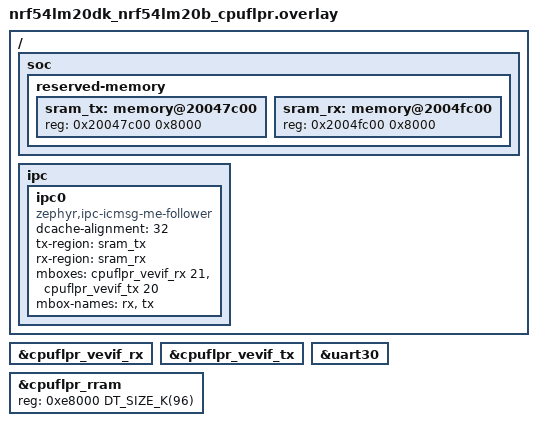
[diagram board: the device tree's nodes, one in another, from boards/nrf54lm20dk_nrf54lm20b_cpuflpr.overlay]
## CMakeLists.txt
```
#
# Copyright (c) 2022 Nordic Semiconductor ASA
#
# SPDX-License-Identifier: Apache-2.0
#

cmake_minimum_required(VERSION 3.20.0)

find_package(Zephyr REQUIRED HINTS $ENV{ZEPHYR_BASE})
project(ipc_service_remote)

target_sources(app PRIVATE src/main.c src/flpr_log_backend.c)
zephyr_include_directories(${CMAKE_CURRENT_SOURCE_DIR}/../include)
```

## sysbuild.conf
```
# FLPR is a sysbuild child image; do not add the VPR bootstrap launcher sample.
SB_CONFIG_VPR_LAUNCHER=n
```

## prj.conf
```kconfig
CONFIG_PRINTK=y
CONFIG_LOG_PRINTK=n

CONFIG_IPC_SERVICE=y
CONFIG_MBOX=y

CONFIG_LOG=y
CONFIG_LOG_DEFAULT_LEVEL=2
CONFIG_LOG_MODE_DEFERRED=y
CONFIG_IPC_SERVICE_LOG_LEVEL_INF=y

CONFIG_HEAP_MEM_POOL_SIZE=2048
```

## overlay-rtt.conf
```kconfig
# Optional: free uart30 - FLPR printk/boot on RTT.
# Operational logs still go over IPC to cpuapp CDC1 (flpr_log_backend).

CONFIG_USE_SEGGER_RTT=y
CONFIG_RTT_CONSOLE=y
CONFIG_UART_CONSOLE=n

# Do not block FLPR boot if no RTT Viewer is attached.
CONFIG_SEGGER_RTT_MODE_NO_BLOCK_SKIP=y
CONFIG_RTT_TX_RETRY_CNT=0

# Keep printk on RTT_CONSOLE; do not enable blocking LOG RTT backend.
CONFIG_LOG_BACKEND_RTT=n
CONFIG_LOG_PRINTK=n
```

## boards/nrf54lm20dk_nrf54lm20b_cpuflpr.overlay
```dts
/ {
	soc {
		reserved-memory {
			#address-cells = <1>;
			#size-cells = <1>;

			sram_tx: memory@20047c00 {
				reg = <0x20047c00 0x8000>;
			};

			sram_rx: memory@2004fc00 {
				reg = <0x2004fc00 0x8000>;
			};
		};
	};

	ipc {
		ipc0: ipc0 {
			compatible = "zephyr,ipc-icmsg-me-follower";
			dcache-alignment = <32>;
			tx-region = <&sram_tx>;
			rx-region = <&sram_rx>;
			mboxes = <&cpuflpr_vevif_rx 21>, <&cpuflpr_vevif_tx 20>;
			mbox-names = "rx", "tx";
			status = "okay";
		};
	};
};

&cpuflpr_vevif_rx {
	status = "okay";
};

&cpuflpr_vevif_tx {
	status = "okay";
};

&uart30 {
	/delete-property/ hw-flow-control;
};

/*
 * Coupled OTA: link FLPR payload at in-slot storage (matches cpuapp
 * cpuflpr_code_partition @ 0xE8000). Node name stays rram@1e5000 (SoC dtsi).
 */
&cpuflpr_rram {
	reg = <0xe8000 DT_SIZE_K(96)>;
	ranges = <0x0 0xe8000 DT_SIZE_K(96)>;
};
```

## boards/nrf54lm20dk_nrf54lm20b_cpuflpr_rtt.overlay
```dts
/*
 * Optional FLPR RTT console - apply with remote/overlay-rtt.conf.
 * Disables debugger uart30; local printk goes to RTT.
 */

/ {
	chosen {
		/delete-property/ zephyr,console;
		/delete-property/ zephyr,shell-uart;
	};
};

&uart30 {
	status = "disabled";
};
```

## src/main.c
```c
#include "flpr_ipc_proto.h"

#include <string.h>

#include <zephyr/device.h>
#include <zephyr/ipc/ipc_service.h>
#include <zephyr/kernel.h>
#include <zephyr/sys/printk.h>

#define STACKSIZE 2048
#define PRIORITY  K_PRIO_PREEMPT(2)

static const struct device *ipc0_dev;
static struct ipc_ept ept_log;
static struct ipc_ept ept_ctrl;

static K_SEM_DEFINE(log_bound_sem, 0, 1);
static K_SEM_DEFINE(ctrl_bound_sem, 0, 1);

static volatile bool log_bound;
static volatile bool ctrl_bound;
static uint32_t heartbeat;

int flpr_remote_send_log(const char *text, size_t len)
{
	if (!log_bound || text == NULL || len == 0) {
		return -ENOTCONN;
	}

	if (len > FLPR_LOG_MAX_LEN) {
		len = FLPR_LOG_MAX_LEN;
	}

	return ipc_service_send(&ept_log, text, len);
}

static void ept_log_bound(void *priv)
{
	ARG_UNUSED(priv);
	log_bound = true;
	k_sem_give(&log_bound_sem);
	/* #region agent log */
	printk("IPC[F] BOUND flpr_log @ %u ms\n", k_uptime_get_32());
	/* #endregion */
	printk("REMOTE: flpr_log bound\n");
}

static void ept_ctrl_bound(void *priv)
{
	ARG_UNUSED(priv);
	ctrl_bound = true;
	k_sem_give(&ctrl_bound_sem);
	/* #region agent log */
	printk("IPC[F] BOUND flpr_ctrl @ %u ms\n", k_uptime_get_32());
	/* #endregion */
	printk("REMOTE: flpr_ctrl bound\n");
}

static int send_ctrl(uint8_t opcode, uint8_t seq, const void *payload, uint16_t payload_len)
{
	uint8_t buf[sizeof(struct flpr_ctrl_hdr) + sizeof(struct flpr_stats) + FLPR_LOG_MAX_LEN];
	struct flpr_ctrl_hdr *hdr = (struct flpr_ctrl_hdr *)buf;

	if (!ctrl_bound) {
		return -ENOTCONN;
	}
	if (payload_len > (sizeof(buf) - sizeof(*hdr))) {
		return -EINVAL;
	}

	hdr->opcode = opcode;
	hdr->seq = seq;
	hdr->len = payload_len;
	if (payload_len && payload != NULL) {
		memcpy(buf + sizeof(*hdr), payload, payload_len);
	}

	return ipc_service_send(&ept_ctrl, buf, sizeof(*hdr) + payload_len);
}

static int send_log_line(const char *text)
{
	return flpr_remote_send_log(text, text ? strlen(text) : 0);
}

static void send_stats(void)
{
	struct flpr_stats stats = {
		.uptime_ms = k_uptime_get_32(),
		.heartbeat = ++heartbeat,
		.free_stack = 0,
	};

	(void)send_ctrl(FLPR_CTRL_OPCODE_STATS, 0, &stats, sizeof(stats));
}

static void ept_log_recv(const void *data, size_t len, void *priv)
{
	ARG_UNUSED(data);
	ARG_UNUSED(len);
	ARG_UNUSED(priv);
}

static void ept_ctrl_recv(const void *data, size_t len, void *priv)
{
	ARG_UNUSED(priv);

	if (data == NULL || len < sizeof(struct flpr_ctrl_hdr)) {
		return;
	}

	const struct flpr_ctrl_hdr *hdr = data;
	const uint8_t *payload = (const uint8_t *)data + sizeof(*hdr);

	switch (hdr->opcode) {
	case FLPR_CTRL_OPCODE_PING:
		(void)send_ctrl(FLPR_CTRL_OPCODE_PONG, hdr->seq, NULL, 0);
		break;
	case FLPR_CTRL_OPCODE_STATS_REQ:
		send_stats();
		break;
	case FLPR_CTRL_OPCODE_LOG_REQ: {
		char line[FLPR_LOG_MAX_LEN + 1];
		uint16_t n = hdr->len;

		if (n > FLPR_LOG_MAX_LEN) {
			n = FLPR_LOG_MAX_LEN;
		}
		if (n > 0) {
			memcpy(line, payload, n);
		}
		line[n] = '\0';
		printk("REMOTE log-req: %s\n", line);
		(void)send_log_line(line);
		break;
	}
	default:
		break;
	}
}

static struct ipc_ept_cfg ept_log_cfg = {
	.name = FLPR_IPC_EPT_LOG_NAME,
	.cb = {
		.bound = ept_log_bound,
		.received = ept_log_recv,
	},
};

static struct ipc_ept_cfg ept_ctrl_cfg = {
	.name = FLPR_IPC_EPT_CTRL_NAME,
	.cb = {
		.bound = ept_ctrl_bound,
		.received = ept_ctrl_recv,
	},
};

static void heartbeat_entry(void *a, void *b, void *c)
{
	ARG_UNUSED(a);
	ARG_UNUSED(b);
	ARG_UNUSED(c);

	while (1) {
		if (ctrl_bound) {
			send_stats();
		}
		if (log_bound) {
			char msg[48];

			snprintk(msg, sizeof(msg), "FLPR heartbeat %u", heartbeat);
			(void)send_log_line(msg);
			printk("%s\n", msg);
		}
		k_sleep(K_SECONDS(5));
	}
}

K_THREAD_DEFINE(hb_tid, STACKSIZE, heartbeat_entry, NULL, NULL, NULL, PRIORITY, 0, 0);

int main(void)
{
	int ret;
	uint32_t t0;

	/* #region agent log */
	printk("IPC[F] main start @ %u ms\n", k_uptime_get_32());
	/* #endregion */
	printk("FLPR remote IPC stub starting\n");

	ipc0_dev = DEVICE_DT_GET(DT_NODELABEL(ipc0));
	if (!device_is_ready(ipc0_dev)) {
		printk("ipc0 not ready\n");
		return 0;
	}

	/* #region agent log */
	printk("IPC[F] open_instance enter @ %u ms\n", k_uptime_get_32());
	/* #endregion */
	ret = ipc_service_open_instance(ipc0_dev);
	/* #region agent log */
	printk("IPC[F] open_instance ret=%d @ %u ms\n", ret, k_uptime_get_32());
	/* #endregion */
	if (ret < 0 && ret != -EALREADY) {
		printk("open_instance failed (%d)\n", ret);
		return 0;
	}

	t0 = k_uptime_get_32();
	/* #region agent log */
	printk("IPC[F] register flpr_log enter @ %u ms\n", t0);
	/* #endregion */
	ret = ipc_service_register_endpoint(ipc0_dev, &ept_log, &ept_log_cfg);
	/* #region agent log */
	printk("IPC[F] register flpr_log ret=%d dt=%u ms\n", ret, k_uptime_get_32() - t0);
	/* #endregion */
	if (ret < 0) {
		printk("register flpr_log failed (%d)\n", ret);
		return 0;
	}

	t0 = k_uptime_get_32();
	/* #region agent log */
	printk("IPC[F] register flpr_ctrl enter @ %u ms\n", t0);
	/* #endregion */
	ret = ipc_service_register_endpoint(ipc0_dev, &ept_ctrl, &ept_ctrl_cfg);
	/* #region agent log */
	printk("IPC[F] register flpr_ctrl ret=%d dt=%u ms\n", ret, k_uptime_get_32() - t0);
	/* #endregion */
	if (ret < 0) {
		printk("register flpr_ctrl failed (%d)\n", ret);
		return 0;
	}

	/* #region agent log */
	printk("IPC[F] sem log wait enter @ %u ms\n", k_uptime_get_32());
	/* #endregion */
	ret = k_sem_take(&log_bound_sem, K_FOREVER);
	/* #region agent log */
	printk("IPC[F] sem log ret=%d @ %u ms\n", ret, k_uptime_get_32());
	/* #endregion */

	/* #region agent log */
	printk("IPC[F] sem ctrl wait enter @ %u ms\n", k_uptime_get_32());
	/* #endregion */
	ret = k_sem_take(&ctrl_bound_sem, K_FOREVER);
	/* #region agent log */
	printk("IPC[F] sem ctrl ret=%d @ %u ms\n", ret, k_uptime_get_32());
	/* #endregion */
	printk("FLPR endpoints bound\n");

	return 0;
}
```

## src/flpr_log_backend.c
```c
#include "flpr_ipc_proto.h"

#include <zephyr/ipc/ipc_service.h>
#include <zephyr/kernel.h>
#include <zephyr/logging/log_backend.h>
#include <zephyr/logging/log_backend_std.h>
#include <zephyr/logging/log_ctrl.h>
#include <zephyr/logging/log_output.h>

extern int flpr_remote_send_log(const char *text, size_t len);

static uint8_t log_buf[FLPR_LOG_MAX_LEN];

static int char_out(uint8_t *data, size_t length, void *ctx)
{
	ARG_UNUSED(ctx);

	if (length == 0) {
		return length;
	}

	/* Drop trailing newlines for cleaner IPC framing. */
	while (length > 0 && (data[length - 1] == '\n' || data[length - 1] == '\r')) {
		length--;
	}

	if (length == 0) {
		return 0;
	}

	if (length > FLPR_LOG_MAX_LEN) {
		length = FLPR_LOG_MAX_LEN;
	}

	(void)flpr_remote_send_log((const char *)data, length);
	return (int)length;
}

LOG_OUTPUT_DEFINE(flpr_log_output, char_out, log_buf, sizeof(log_buf));

static void panic(struct log_backend const *const backend)
{
	ARG_UNUSED(backend);
}

static void dropped(const struct log_backend *const backend, uint32_t cnt)
{
	ARG_UNUSED(backend);
	ARG_UNUSED(cnt);
}

static void process(const struct log_backend *const backend, union log_msg_generic *msg)
{
	ARG_UNUSED(backend);

	log_format_func_t func = log_format_func_t_get(LOG_OUTPUT_TEXT);

	func(&flpr_log_output, &msg->log, log_backend_std_get_flags());
}

static int format_set(const struct log_backend *const backend, uint32_t log_type)
{
	ARG_UNUSED(backend);
	ARG_UNUSED(log_type);
	return 0;
}

static const struct log_backend_api flpr_log_api = {
	.process = process,
	.panic = panic,
	.dropped = dropped,
	.format_set = format_set,
};

LOG_BACKEND_DEFINE(flpr_ipc_log_backend, flpr_log_api, true);
```
